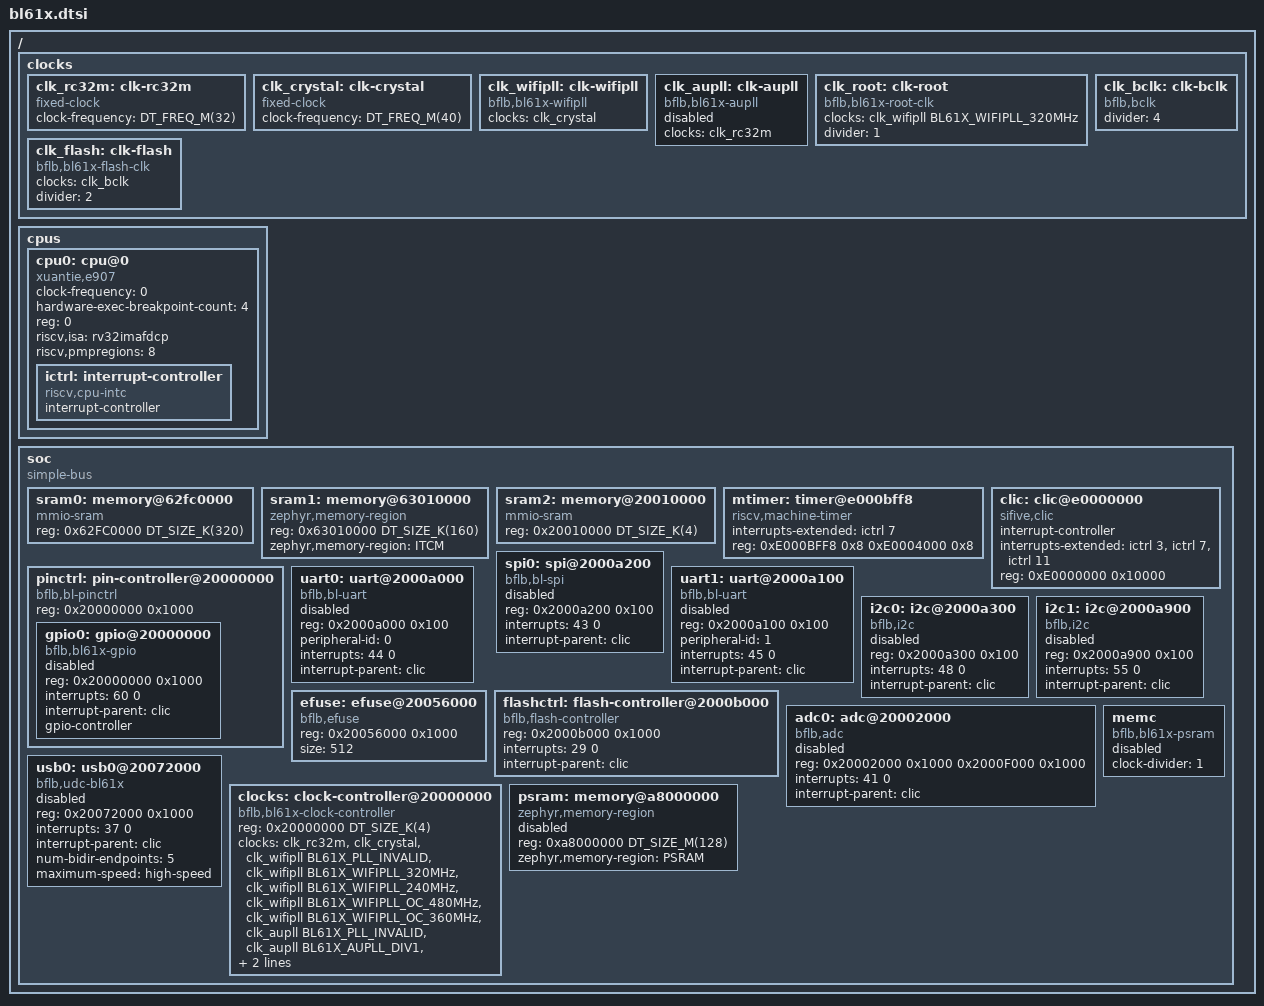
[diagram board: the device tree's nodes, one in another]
/*
 * Copyright (c) 2024-2025 MASSDRIVER EI (massdriver.space)
 *
 * SPDX-License-Identifier: Apache-2.0
 */

#include <mem.h>
#include <freq.h>
#include <dt-bindings/pinctrl/bl61x-pinctrl.h>
#include <dt-bindings/pinctrl/bflb-common-pinctrl.h>
#include <zephyr/dt-bindings/adc/adc.h>
#include <zephyr/dt-bindings/gpio/gpio.h>
#include <zephyr/dt-bindings/i2c/i2c.h>
#include <zephyr/dt-bindings/spi/spi.h>
#include <zephyr/dt-bindings/input/input-event-codes.h>
#include <dt-bindings/clock/bflb_bl61x_clock.h>


/ {
	#address-cells = <1>;
	#size-cells = <1>;

	clocks {
		clk_rc32m: clk-rc32m {
			#clock-cells = <0>;
			compatible = "fixed-clock";
			clock-frequency = <DT_FREQ_M(32)>;
			status = "okay";
		};

		clk_crystal: clk-crystal {
			#clock-cells = <0>;
			compatible = "fixed-clock";
			clock-frequency = <DT_FREQ_M(40)>;
			status = "okay";
		};

		clk_wifipll: clk-wifipll {
			#clock-cells = <1>;
			compatible = "bflb,bl61x-wifipll";
			clocks = <&clk_crystal>;
			status = "okay";
		};

		clk_aupll: clk-aupll {
			#clock-cells = <1>;
			compatible = "bflb,bl61x-aupll";
			clocks = <&clk_rc32m>;
			status = "disabled";
		};

		clk_root: clk-root {
			#clock-cells = <0>;
			compatible = "bflb,bl61x-root-clk";
			clocks = <&clk_wifipll BL61X_WIFIPLL_320MHz>;
			divider = <1>;
			status = "okay";
		};

		clk_bclk: clk-bclk {
			#clock-cells = <0>;
			compatible = "bflb,bclk";
			divider = <4>;
			status = "okay";
		};

		clk_flash: clk-flash {
			#clock-cells = <0>;
			compatible = "bflb,bl61x-flash-clk";
			clocks = <&clk_bclk>;
			divider = <2>;
			status = "okay";
		};
	};

	cpus {
		#address-cells = <1>;
		#size-cells = <0>;

		cpu0: cpu@0 {
			clock-frequency = <0>;
			compatible = "xuantie,e907", "riscv";
			device_type = "cpu";
			hardware-exec-breakpoint-count = <4>;
			reg = <0>;
			riscv,isa = "rv32imafdcp";
			riscv,pmpregions = <8>;

			ictrl: interrupt-controller {
				#address-cells = <0>;
				#interrupt-cells = <1>;
				compatible = "riscv,cpu-intc";
				interrupt-controller;
			};
		};
	};

	soc {
		#address-cells = <1>;
		#size-cells = <1>;
		compatible = "simple-bus";
		ranges;

		sram0: memory@62fc0000 {
			compatible = "mmio-sram";
			reg = <0x62FC0000 DT_SIZE_K(320)>;
		};
		sram1: memory@63010000 {
			compatible = "zephyr,memory-region", "mmio-sram";
			reg = <0x63010000 DT_SIZE_K(160)>;
			zephyr,memory-region = "ITCM";
		};
		sram2: memory@20010000 {
			compatible = "mmio-sram";
			reg = <0x20010000 DT_SIZE_K(4)>;
		};

		mtimer: timer@e000bff8 {
			compatible = "riscv,machine-timer";
			interrupts-extended = <&ictrl 7>;
			reg = <0xE000BFF8 0x8 0xE0004000 0x8>;
			reg-names = "mtime", "mtimecmp";
		};

		clic: clic@e0000000 {
			#interrupt-cells = <2>;
			interrupt-controller;
			compatible = "sifive,clic";
			interrupts-extended = <&ictrl 3 &ictrl 7 &ictrl 11>;
			reg = <0xE0000000 0x10000>;
			reg-names = "control";
/*
			sifive,numintbits = <4>;
			sifive,numints = <64>;
			sifive,numlevels = <16>;
*/
		};

		pinctrl: pin-controller@20000000 {
			compatible = "bflb,bl-pinctrl";
			reg = <0x20000000 0x1000>;
			#address-cells = <1>;
			#size-cells = <1>;
			ranges = <0x20000000 0x20000000 0x1000>;
			status = "okay";

			gpio0: gpio@20000000 {
				compatible = "bflb,bl61x-gpio";
				reg = <0x20000000 0x1000>;
				interrupts = <60 0>;
				interrupt-parent = <&clic>;
				gpio-controller;
				#gpio-cells = <2>;
				#bflb,pin-cells = <2>;
				status = "disabled";
			};
		};

		spi0: spi@2000a200 {
			compatible = "bflb,bl-spi";
			reg = <0x2000a200 0x100>;
			interrupts = <43 0>;
			interrupt-parent = <&clic>;
			status = "disabled";
			#address-cells = <1>;
			#size-cells = <0>;
		};

		uart0: uart@2000a000 {
			compatible = "bflb,bl-uart";
			reg = <0x2000a000 0x100>;
			peripheral-id = <0>;
			interrupts = <44 0>;
			interrupt-parent = <&clic>;
			status = "disabled";
		};
		uart1: uart@2000a100 {
			compatible = "bflb,bl-uart";
			reg = <0x2000a100 0x100>;
			peripheral-id = <1>;
			interrupts = <45 0>;
			interrupt-parent = <&clic>;
			status = "disabled";
		};
		i2c0: i2c@2000a300 {
			compatible = "bflb,i2c";
			reg = <0x2000a300 0x100>;
			interrupts = <48 0>;
			interrupt-parent = <&clic>;
			status = "disabled";
			#address-cells = <1>;
			#size-cells = <0>;
		};
		i2c1: i2c@2000a900 {
			compatible = "bflb,i2c";
			reg = <0x2000a900 0x100>;
			interrupts = <55 0>;
			interrupt-parent = <&clic>;
			status = "disabled";
			#address-cells = <1>;
			#size-cells = <0>;
		};
		efuse: efuse@20056000 {
			compatible = "bflb,efuse";
			reg = <0x20056000 0x1000>;
			status = "okay";
			size = <512>;
		};
		flashctrl: flash-controller@2000b000 {
			compatible = "bflb,flash-controller";
			reg = <0x2000b000 0x1000>;

			#address-cells = <1>;
			#size-cells = <1>;
			interrupts = <29 0>;
			interrupt-parent = <&clic>;
			status = "okay";
		};
		adc0: adc@20002000 {
			compatible = "bflb,adc";
			/* GPIP reg, AON REG */
			reg = <0x20002000 0x1000 0x2000F000 0x1000>;
			interrupts = <41 0>;
			interrupt-parent = <&clic>;
			#io-channel-cells = <1>;
			status = "disabled";
		};
		usb0: usb0@20072000 {
			compatible = "bflb,udc-bl61x";
			reg = <0x20072000 0x1000>;
			interrupts = <37 0>;
			interrupt-parent = <&clic>;
			num-bidir-endpoints = <5>;
			maximum-speed = "high-speed";
			status = "disabled";
		};
		clocks: clock-controller@20000000 {
			compatible = "bflb,bl61x-clock-controller", "bflb,clock-controller";
			reg = <0x20000000 DT_SIZE_K(4)>;
			#clock-cells = <1>;
			status = "okay";
			clocks = <&clk_rc32m>, <&clk_crystal>,
				<&clk_wifipll BL61X_PLL_INVALID>,
				<&clk_wifipll BL61X_WIFIPLL_320MHz>,
				<&clk_wifipll BL61X_WIFIPLL_240MHz>,
				<&clk_wifipll BL61X_WIFIPLL_OC_480MHz>,
				<&clk_wifipll BL61X_WIFIPLL_OC_360MHz>,
				<&clk_aupll BL61X_PLL_INVALID>,
				<&clk_aupll BL61X_AUPLL_DIV1>, <&clk_aupll BL61X_AUPLL_DIV2>,
				<&clk_root>, <&clk_bclk>, <&clk_flash>;
			clock-names = "rc32m", "crystal",
				"wifipll",
				"wifipll_320",
				"wifipll_240",
				"wifipll_480",
				"wifipll_360",
				"aupll",
				"aupll_div1", "aupll_div2",
				"root", "bclk", "flash";
		};
		psram: memory@a8000000 {
			compatible = "zephyr,memory-region";
			reg = <0xa8000000 DT_SIZE_M(128)>;
			zephyr,memory-region = "PSRAM";
			status = "disabled";
		};
		memc: memc {
			compatible = "bflb,bl61x-psram";
			clock-divider = <1>;
			status = "disabled";
		};
	};
};
